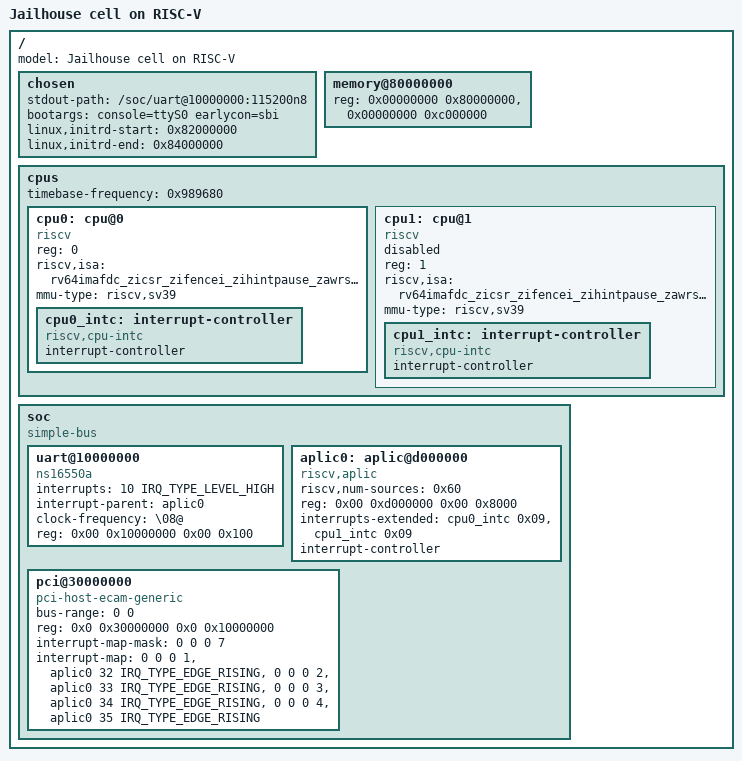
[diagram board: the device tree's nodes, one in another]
/*
 * Jailhouse, a Linux-based partitioning hypervisor
 *
 * Copyright (c) OTH Regensburg, 2022-2024
 *
 * Authors:
 *  Ralf Ramsauer <ralf.ramsauer@oth-regensburg.de>
 *
 * This work is licensed under the terms of the GNU GPL, version 2.  See
 * the COPYING file in the top-level directory.
 */

#define IRQ_TYPE_EDGE_RISING	1
#define IRQ_TYPE_LEVEL_HIGH	4

/dts-v1/;
/ {
	model = "Jailhouse cell on RISC-V";

	#address-cells = <2>;
	#size-cells = <2>;

	chosen {
		stdout-path = "/soc/uart@10000000:115200n8";
		bootargs = "console=ttyS0 earlycon=sbi";
		linux,initrd-start = <0x82000000>;
		linux,initrd-end = <0x84000000>;
	};

	memory@80000000 {
		device_type = "memory";
		/* 63MiB @ 0x80000000 */
		reg = <0x00000000 0x80000000>, <0x00000000 0xc000000>;
	};

	cpus {
		#address-cells = <1>;
		#size-cells = <0>;
		timebase-frequency = <0x989680>;

		cpu0: cpu@0 {
			device_type = "cpu";
			reg = <0>;
			status = "okay";
			compatible = "riscv";
			riscv,isa = "rv64imafdc_zicsr_zifencei_zihintpause_zawrs_zba_zbb_zbc_zbs_sstc";
			mmu-type = "riscv,sv39";

			cpu0_intc: interrupt-controller {
				#interrupt-cells = <1>;
				compatible = "riscv,cpu-intc";
				interrupt-controller;
			};
		};

		cpu1: cpu@1 {
			device_type = "cpu";
			reg = <1>;
			status = "disabled";
			compatible = "riscv";
			riscv,isa = "rv64imafdc_zicsr_zifencei_zihintpause_zawrs_zba_zbb_zbc_zbs_sstc";
			mmu-type = "riscv,sv39";

			cpu1_intc: interrupt-controller {
				#interrupt-cells = <1>;
				compatible = "riscv,cpu-intc";
				interrupt-controller;
			};
		};
	};
	soc {
		#address-cells = <2>;
		#size-cells = <2>;
		compatible = "simple-bus";
		ranges;

		uart@10000000 {
			interrupts = <10 IRQ_TYPE_LEVEL_HIGH>;
			interrupt-parent = <&aplic0>;
			clock-frequency = "\08@";
			reg = <0x00 0x10000000 0x00 0x100>;
			compatible = "ns16550a";
			status = "okay";
		};

		/* S-Mode APLIC */
		aplic0: aplic@d000000 {
			riscv,num-sources = <0x60>;
			reg = <0x00 0xd000000 0x00 0x8000>;
			interrupts-extended = <&cpu0_intc 0x09>,
					      <&cpu1_intc 0x09>;
			interrupt-controller;
			#interrupt-cells = <0x02>;
			compatible = "riscv,aplic";
		};

		pci@30000000 {
			compatible = "pci-host-ecam-generic";
			device_type = "pci";
			bus-range = <0 0>;
			#interrupt-cells = <1>;
			reg = <0x0 0x30000000 0x0 0x10000000>;
			#address-cells = <3>;
			#size-cells = <2>;
			ranges =
				<0x1000000 0x00 0x00 0x00 0x3000000 0x00 0x10000>,
				<0x2000000 0x00 0x40000000 0x00 0x40000000 0x00 0x40000000>,
				<0x3000000 0x04 0x00 0x04 0x00 0x04 0x00>;

			interrupt-map-mask = <0 0 0 7>;
			interrupt-map = <0 0 0 1 &aplic0 32 IRQ_TYPE_EDGE_RISING>,
					<0 0 0 2 &aplic0 33 IRQ_TYPE_EDGE_RISING>,
					<0 0 0 3 &aplic0 34 IRQ_TYPE_EDGE_RISING>,
					<0 0 0 4 &aplic0 35 IRQ_TYPE_EDGE_RISING>;
		};
	};
};
